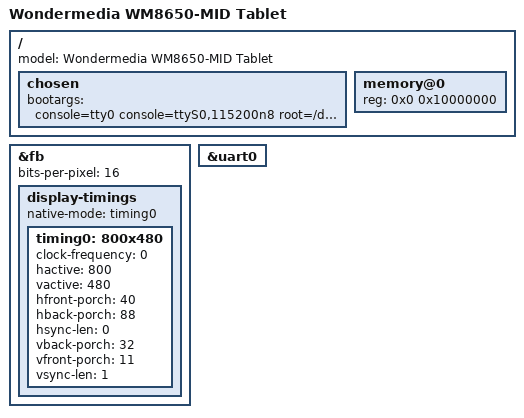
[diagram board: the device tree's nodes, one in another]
// SPDX-License-Identifier: GPL-2.0-or-later
/*
 * wm8650-mid.dts - Device tree file for Wondermedia WM8650-MID Tablet
 *
 * Copyright (C) 2012 Tony Prisk <linux@prisktech.co.nz>
 */

/dts-v1/;
/include/ "wm8650.dtsi"

/ {
	model = "Wondermedia WM8650-MID Tablet";

	chosen {
		bootargs = "console=tty0 console=ttyS0,115200n8 root=/dev/mmcblk0p2 rootwait rw panic=10";
	};

	memory@0 {
		device_type = "memory";
		reg = <0x0 0x10000000>; /* 256MB DDR2 RAM */
	};
};

&fb {
	bits-per-pixel = <16>;

	display-timings {
		native-mode = <&timing0>;
		timing0: 800x480 {
			clock-frequency = <0>; /* unused but required */
			hactive = <800>;
			vactive = <480>;
			hfront-porch = <40>;
			hback-porch = <88>;
			hsync-len = <0>;
			vback-porch = <32>;
			vfront-porch = <11>;
			vsync-len = <1>;
		};
	};
};

&uart0 {
	status = "okay";
};
